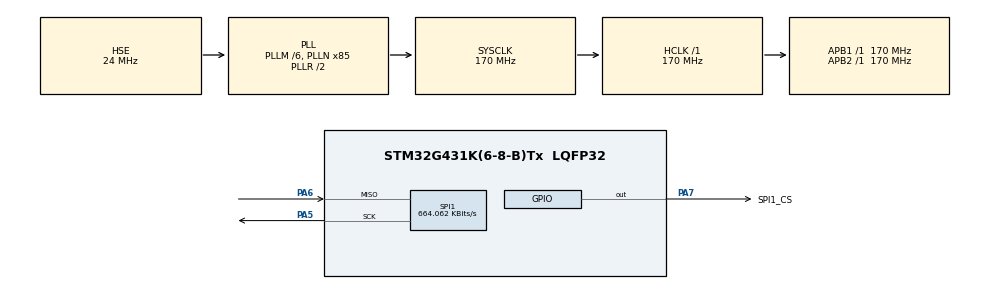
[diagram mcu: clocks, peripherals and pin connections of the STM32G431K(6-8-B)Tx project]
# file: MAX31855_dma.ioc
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Dma.Request0=SPI1_RX
Dma.SPI1_RX.0.Direction=DMA_PERIPH_TO_MEMORY
Dma.SPI1_RX.0.EventEnable=DISABLE
Dma.SPI1_RX.0.Instance=DMA1_Channel1
Dma.SPI1_RX.0.MemDataAlignment=DMA_MDATAALIGN_BYTE
Dma.SPI1_RX.0.MemInc=DMA_MINC_ENABLE
Dma.SPI1_RX.0.Mode=DMA_NORMAL
Dma.SPI1_RX.0.PeriphDataAlignment=DMA_PDATAALIGN_BYTE
Dma.SPI1_RX.0.PeriphInc=DMA_PINC_DISABLE
Dma.SPI1_RX.0.Polarity=HAL_DMAMUX_REQ_GEN_RISING
Dma.SPI1_RX.0.Priority=DMA_PRIORITY_LOW
Dma.SPI1_RX.0.RequestNumber=1
Dma.SPI1_RX.0.SignalID=NONE
Dma.SPI1_RX.0.SyncEnable=DISABLE
Dma.SPI1_RX.0.SyncPolarity=HAL_DMAMUX_SYNC_NO_EVENT
Dma.SPI1_RX.0.SyncRequestNumber=1
Dma.SPI1_RX.0.SyncSignalID=NONE
Mcu.Family=STM32G4
Mcu.Name=STM32G431K(6-8-B)Tx
Mcu.Package=LQFP32
NVIC.DMA1_Channel1_IRQn=true\:0\:0\:false\:false\:true\:false\:true\:true
NVIC.PriorityGroup=NVIC_PRIORITYGROUP_4
NVIC.SPI1_IRQn=true\:0\:0\:false\:false\:true\:true\:true\:true
PA13.Mode=Serial_Wire
PA13.Signal=SYS_JTMS-SWDIO
PA14.Mode=Serial_Wire
PA14.Signal=SYS_JTCK-SWCLK
PA5.Mode=RX_Only_Simplex_Unidirect_Master
PA5.Signal=SPI1_SCK
PA6.Mode=RX_Only_Simplex_Unidirect_Master
PA6.Signal=SPI1_MISO
PA7.GPIO_Label=SPI1_CS
PA7.Signal=GPIO_Output
PF0-OSC_IN.Mode=HSE-External-Oscillator
PF0-OSC_IN.Signal=RCC_OSC_IN
PF1-OSC_OUT.Mode=HSE-External-Oscillator
PF1-OSC_OUT.Signal=RCC_OSC_OUT
ProjectManager.HeapSize=0x200
ProjectManager.StackSize=0x400
ProjectManager.TargetToolchain=STM32CubeIDE
RCC.ADC12Freq_Value=170000000
RCC.AHBFreq_Value=170000000
RCC.APB1Freq_Value=170000000
RCC.APB1TimFreq_Value=170000000
RCC.APB2Freq_Value=170000000
RCC.APB2TimFreq_Value=170000000
RCC.CortexFreq_Value=170000000
RCC.EXTERNAL_CLOCK_VALUE=12288000
RCC.HCLKFreq_Value=170000000
RCC.HSE_VALUE=24000000
RCC.HSI48_VALUE=48000000
RCC.HSI_VALUE=16000000
RCC.LSE_VALUE=32768
RCC.PLLM=RCC_PLLM_DIV6
RCC.PLLN=85
RCC.PLLSourceVirtual=RCC_PLLSOURCE_HSE
RCC.SYSCLKFreq_VALUE=170000000
RCC.SYSCLKSource=RCC_SYSCLKSOURCE_PLLCLK
RCC.USBFreq_Value=170000000
RCC.VCOOutputFreq_Value=340000000
SPI1.BaudRatePrescaler=SPI_BAUDRATEPRESCALER_256
SPI1.CalculateBaudRate=664.062 KBits/s
SPI1.DataSize=SPI_DATASIZE_8BIT
SPI1.Direction=SPI_DIRECTION_2LINES_RXONLY
SPI1.Mode=SPI_MODE_MASTER
SPI1.VirtualType=VM_MASTER
VP_SYS_VS_DBSignals.Mode=DisableDeadBatterySignals
board=custom

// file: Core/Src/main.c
/* USER CODE BEGIN Header */
/**
  ******************************************************************************
  * @file           : main.c
  * @brief          : Main program body
  ******************************************************************************
  * @attention
  *
  * Copyright (c) 2026 STMicroelectronics.
  * All rights reserved.
  *
  * This software is licensed under terms that can be found in the LICENSE file
  * in the root directory of this software component.
  * If no LICENSE file comes with this software, it is provided AS-IS.
  *
  ******************************************************************************
  */
/* USER CODE END Header */
#include "main.h"

/* USER CODE BEGIN Includes */
#include "max31855.h"
/* USER CODE END Includes */

SPI_HandleTypeDef hspi1;
DMA_HandleTypeDef hdma_spi1_rx;

/* USER CODE BEGIN PV */
static MAX31855_Handle_t max31855Handle;
static float             temperatureC         = 0.0f;
static float             temperatureF         = 0.0f;
static float             internalTemperatureC = 0.0f;
/* USER CODE END PV */

void SystemClock_Config(void);
static void MX_GPIO_Init(void);
static void MX_DMA_Init(void);
static void MX_SPI1_Init(void);

int main(void)
{

  /* MCU Configuration--------------------------------------------------------*/

  /* Reset of all peripherals, Initializes the Flash interface and the Systick. */
  HAL_Init();

  /* Configure the system clock */
  SystemClock_Config();

  /* Initialize all configured peripherals */
  MX_GPIO_Init();
  MX_DMA_Init();
  MX_SPI1_Init();
  /* USER CODE BEGIN 2 */
  if (MAX31855_Init(&max31855Handle, &hspi1, SPI1_CS_GPIO_Port, SPI1_CS_Pin, 100u, MAX31855_MODE_DMA) != MAX31855_STATUS_OK)
  {
    Error_Handler();
  }
  /* USER CODE END 2 */

  /* Infinite loop */
  while (1)
  {

    /* USER CODE BEGIN 3 */
    if (MAX31855_StartRead(&max31855Handle) == MAX31855_STATUS_OK)
    {
      while (MAX31855_GetReadStatus(&max31855Handle) == MAX31855_STATUS_BUSY)
      {

      }

      MAX31855_GetTemperatureC(&max31855Handle, &temperatureC);
      MAX31855_GetTemperatureF(&max31855Handle, &temperatureF);
      MAX31855_GetInternalTemperatureC(&max31855Handle, &internalTemperatureC);
    }

    HAL_Delay(MAX31855_CONVERSION_TIME_MS);
  }
  /* USER CODE END 3 */
}

void SystemClock_Config(void)
{
  RCC_OscInitTypeDef RCC_OscInitStruct = {0};
  RCC_ClkInitTypeDef RCC_ClkInitStruct = {0};

  /** Configure the main internal regulator output voltage
  */
  HAL_PWREx_ControlVoltageScaling(PWR_REGULATOR_VOLTAGE_SCALE1_BOOST);

  /** Initializes the RCC Oscillators according to the specified parameters
  * in the RCC_OscInitTypeDef structure.
  */
  RCC_OscInitStruct.OscillatorType = RCC_OSCILLATORTYPE_HSE;
  RCC_OscInitStruct.HSEState = RCC_HSE_ON;
  RCC_OscInitStruct.PLL.PLLState = RCC_PLL_ON;
  RCC_OscInitStruct.PLL.PLLSource = RCC_PLLSOURCE_HSE;
  RCC_OscInitStruct.PLL.PLLM = RCC_PLLM_DIV6;
  RCC_OscInitStruct.PLL.PLLN = 85;
  RCC_OscInitStruct.PLL.PLLP = RCC_PLLP_DIV2;
  RCC_OscInitStruct.PLL.PLLQ = RCC_PLLQ_DIV2;
  RCC_OscInitStruct.PLL.PLLR = RCC_PLLR_DIV2;
  if (HAL_RCC_OscConfig(&RCC_OscInitStruct) != HAL_OK)
  {
    Error_Handler();
  }

  /** Initializes the CPU, AHB and APB buses clocks
  */
  RCC_ClkInitStruct.ClockType = RCC_CLOCKTYPE_HCLK|RCC_CLOCKTYPE_SYSCLK
                              |RCC_CLOCKTYPE_PCLK1|RCC_CLOCKTYPE_PCLK2;
  RCC_ClkInitStruct.SYSCLKSource = RCC_SYSCLKSOURCE_PLLCLK;
  RCC_ClkInitStruct.AHBCLKDivider = RCC_SYSCLK_DIV1;
  RCC_ClkInitStruct.APB1CLKDivider = RCC_HCLK_DIV1;
  RCC_ClkInitStruct.APB2CLKDivider = RCC_HCLK_DIV1;

  if (HAL_RCC_ClockConfig(&RCC_ClkInitStruct, FLASH_LATENCY_4) != HAL_OK)
  {
    Error_Handler();
  }
}

static void MX_SPI1_Init(void)
{

  /* SPI1 parameter configuration*/
  hspi1.Instance = SPI1;
  hspi1.Init.Mode = SPI_MODE_MASTER;
  hspi1.Init.Direction = SPI_DIRECTION_2LINES_RXONLY;
  hspi1.Init.DataSize = SPI_DATASIZE_8BIT;
  hspi1.Init.CLKPolarity = SPI_POLARITY_LOW;
  hspi1.Init.CLKPhase = SPI_PHASE_1EDGE;
  hspi1.Init.NSS = SPI_NSS_SOFT;
  hspi1.Init.BaudRatePrescaler = SPI_BAUDRATEPRESCALER_256;
  hspi1.Init.FirstBit = SPI_FIRSTBIT_MSB;
  hspi1.Init.TIMode = SPI_TIMODE_DISABLE;
  hspi1.Init.CRCCalculation = SPI_CRCCALCULATION_DISABLE;
  hspi1.Init.CRCPolynomial = 7;
  hspi1.Init.CRCLength = SPI_CRC_LENGTH_DATASIZE;
  hspi1.Init.NSSPMode = SPI_NSS_PULSE_ENABLE;
  if (HAL_SPI_Init(&hspi1) != HAL_OK)
  {
    Error_Handler();
  }

}

static void MX_DMA_Init(void)
{

  /* DMA controller clock enable */
  __HAL_RCC_DMAMUX1_CLK_ENABLE();
  __HAL_RCC_DMA1_CLK_ENABLE();

  /* DMA interrupt init */
  /* DMA1_Channel1_IRQn interrupt configuration */
  HAL_NVIC_SetPriority(DMA1_Channel1_IRQn, 0, 0);
  HAL_NVIC_EnableIRQ(DMA1_Channel1_IRQn);

}

static void MX_GPIO_Init(void)
{
  GPIO_InitTypeDef GPIO_InitStruct = {0};

  /* GPIO Ports Clock Enable */
  __HAL_RCC_GPIOF_CLK_ENABLE();
  __HAL_RCC_GPIOA_CLK_ENABLE();

  /*Configure GPIO pin Output Level */
  HAL_GPIO_WritePin(SPI1_CS_GPIO_Port, SPI1_CS_Pin, GPIO_PIN_RESET);

  /*Configure GPIO pin : SPI1_CS_Pin */
  GPIO_InitStruct.Pin = SPI1_CS_Pin;
  GPIO_InitStruct.Mode = GPIO_MODE_OUTPUT_PP;
  GPIO_InitStruct.Pull = GPIO_NOPULL;
  GPIO_InitStruct.Speed = GPIO_SPEED_FREQ_LOW;
  HAL_GPIO_Init(SPI1_CS_GPIO_Port, &GPIO_InitStruct);

}

void Error_Handler(void)
{
  __disable_irq();
  while (1)
  {
  }
}
